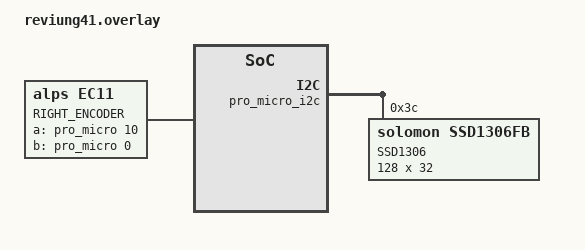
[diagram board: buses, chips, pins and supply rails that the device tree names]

/{
    right_encoder: encoder_right {
        compatible = "alps,ec11";
        label = "RIGHT_ENCODER";
        a-gpios = <&pro_micro 10 (GPIO_ACTIVE_HIGH | GPIO_PULL_UP)>;
        b-gpios = <&pro_micro 0  (GPIO_ACTIVE_HIGH | GPIO_PULL_UP)>;
        resolution = <2>;
        status = "okay";
    };

    sensors {
        compatible = "zmk,keymap-sensors";
        sensors = <&right_encoder>;
    };

};

&pro_micro_i2c {
  status = "okay";

  oled: ssd1306@3c {
    compatible = "solomon,ssd1306fb";
    reg = <0x3c>;
    label = "SSD1306";
    width = <128>;
    height = <32>;
    segment-offset = <0>;
    page-offset = <0>;
    display-offset = <0>;
    multiplex-ratio = <31>;
    com-invdir;
    segment-remap;
    com-sequential;
    prechargep = <0x22>;
  };
};

/ {
  chosen {
    zephyr,display = &oled;
  };
};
